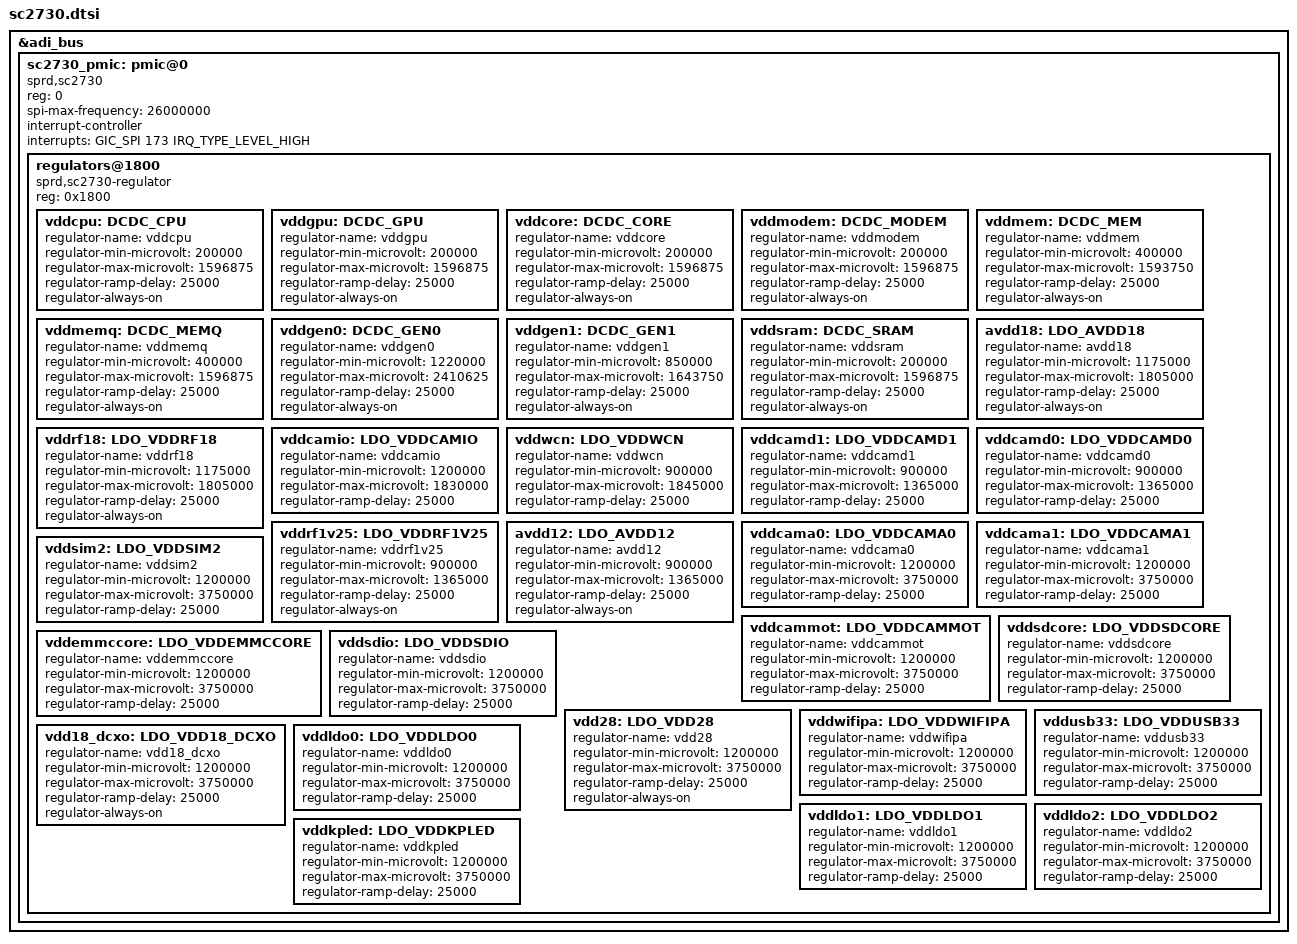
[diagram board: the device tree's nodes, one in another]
// SPDX-License-Identifier: (GPL-2.0 OR MIT)
/*
 * Unisoc SC2730 PMIC dts file
 *
 * Copyright (C) 2021, Unisoc Inc.
 */

&adi_bus {
	sc2730_pmic: pmic@0 {
		compatible = "sprd,sc2730";
		reg = <0>;
		spi-max-frequency = <26000000>;
		interrupt-controller;
		#interrupt-cells = <1>;
		interrupts = <GIC_SPI 173 IRQ_TYPE_LEVEL_HIGH>;
		#address-cells = <1>;
		#size-cells = <0>;

		regulators@1800 {
			compatible = "sprd,sc2730-regulator";
			reg = <0x1800>;

			vddcpu: DCDC_CPU {
				regulator-name = "vddcpu";
				regulator-min-microvolt = <200000>;
				regulator-max-microvolt = <1596875>;
				regulator-ramp-delay = <25000>;
				regulator-always-on;
			};

			vddgpu: DCDC_GPU {
				regulator-name = "vddgpu";
				regulator-min-microvolt = <200000>;
				regulator-max-microvolt = <1596875>;
				regulator-ramp-delay = <25000>;
				regulator-always-on;
			};

			vddcore: DCDC_CORE {
				regulator-name = "vddcore";
				regulator-min-microvolt = <200000>;
				regulator-max-microvolt = <1596875>;
				regulator-ramp-delay = <25000>;
				regulator-always-on;
			};

			vddmodem: DCDC_MODEM {
				regulator-name = "vddmodem";
				regulator-min-microvolt = <200000>;
				regulator-max-microvolt = <1596875>;
				regulator-ramp-delay = <25000>;
				regulator-always-on;
			};

			vddmem: DCDC_MEM {
				regulator-name = "vddmem";
				regulator-min-microvolt = <400000>;
				regulator-max-microvolt = <1593750>;
				regulator-ramp-delay = <25000>;
				regulator-always-on;
			};

			vddmemq: DCDC_MEMQ {
				regulator-name = "vddmemq";
				regulator-min-microvolt = <400000>;
				regulator-max-microvolt = <1596875>;
				regulator-ramp-delay = <25000>;
				regulator-always-on;
			};

			vddgen0: DCDC_GEN0 {
				regulator-name = "vddgen0";
				regulator-min-microvolt = <1220000>;
				regulator-max-microvolt = <2410625>;
				regulator-ramp-delay = <25000>;
				regulator-always-on;
			};

			vddgen1: DCDC_GEN1 {
				regulator-name = "vddgen1";
				regulator-min-microvolt = <850000>;
				regulator-max-microvolt = <1643750>;
				regulator-ramp-delay = <25000>;
				regulator-always-on;
			};

			vddsram: DCDC_SRAM {
				regulator-name = "vddsram";
				regulator-min-microvolt = <200000>;
				regulator-max-microvolt = <1596875>;
				regulator-ramp-delay = <25000>;
				regulator-always-on;
			};

			avdd18: LDO_AVDD18 {
				regulator-name = "avdd18";
				regulator-min-microvolt = <1175000>;
				regulator-max-microvolt = <1805000>;
				regulator-ramp-delay = <25000>;
				regulator-always-on;
			};

			vddrf18: LDO_VDDRF18 {
				regulator-name = "vddrf18";
				regulator-min-microvolt = <1175000>;
				regulator-max-microvolt = <1805000>;
				regulator-ramp-delay = <25000>;
				regulator-always-on;
			};

			vddcamio: LDO_VDDCAMIO {
				regulator-name = "vddcamio";
				regulator-min-microvolt = <1200000>;
				regulator-max-microvolt = <1830000>;
				regulator-ramp-delay = <25000>;
			};

			vddwcn: LDO_VDDWCN {
				regulator-name = "vddwcn";
				regulator-min-microvolt = <900000>;
				regulator-max-microvolt = <1845000>;
				regulator-ramp-delay = <25000>;
			};

			vddcamd1: LDO_VDDCAMD1 {
				regulator-name = "vddcamd1";
				regulator-min-microvolt = <900000>;
				regulator-max-microvolt = <1365000>;
				regulator-ramp-delay = <25000>;
			};

			vddcamd0: LDO_VDDCAMD0 {
				regulator-name = "vddcamd0";
				regulator-min-microvolt = <900000>;
				regulator-max-microvolt = <1365000>;
				regulator-ramp-delay = <25000>;
			};

			vddrf1v25: LDO_VDDRF1V25 {
				regulator-name = "vddrf1v25";
				regulator-min-microvolt = <900000>;
				regulator-max-microvolt = <1365000>;
				regulator-ramp-delay = <25000>;
				regulator-always-on;
			};

			avdd12: LDO_AVDD12 {
				regulator-name = "avdd12";
				regulator-min-microvolt = <900000>;
				regulator-max-microvolt = <1365000>;
				regulator-ramp-delay = <25000>;
				regulator-always-on;
			};

			vddcama0: LDO_VDDCAMA0 {
				regulator-name = "vddcama0";
				regulator-min-microvolt = <1200000>;
				regulator-max-microvolt = <3750000>;
				regulator-ramp-delay = <25000>;
			};

			vddcama1: LDO_VDDCAMA1 {
				regulator-name = "vddcama1";
				regulator-min-microvolt = <1200000>;
				regulator-max-microvolt = <3750000>;
				regulator-ramp-delay = <25000>;
			};

			vddcammot: LDO_VDDCAMMOT {
				regulator-name = "vddcammot";
				regulator-min-microvolt = <1200000>;
				regulator-max-microvolt = <3750000>;
				regulator-ramp-delay = <25000>;
			};

			vddsim2: LDO_VDDSIM2 {
				regulator-name = "vddsim2";
				regulator-min-microvolt = <1200000>;
				regulator-max-microvolt = <3750000>;
				regulator-ramp-delay = <25000>;
			};

			vddemmccore: LDO_VDDEMMCCORE {
				regulator-name = "vddemmccore";
				regulator-min-microvolt = <1200000>;
				regulator-max-microvolt = <3750000>;
				regulator-ramp-delay = <25000>;
			};

			vddsdcore: LDO_VDDSDCORE {
				regulator-name = "vddsdcore";
				regulator-min-microvolt = <1200000>;
				regulator-max-microvolt = <3750000>;
				regulator-ramp-delay = <25000>;
			};

			vddsdio: LDO_VDDSDIO {
				regulator-name = "vddsdio";
				regulator-min-microvolt = <1200000>;
				regulator-max-microvolt = <3750000>;
				regulator-ramp-delay = <25000>;
			};

			vdd28: LDO_VDD28 {
				regulator-name = "vdd28";
				regulator-min-microvolt = <1200000>;
				regulator-max-microvolt = <3750000>;
				regulator-ramp-delay = <25000>;
				regulator-always-on;
			};

			vddwifipa: LDO_VDDWIFIPA {
				regulator-name = "vddwifipa";
				regulator-min-microvolt = <1200000>;
				regulator-max-microvolt = <3750000>;
				regulator-ramp-delay = <25000>;
			};

			vdd18_dcxo: LDO_VDD18_DCXO {
				regulator-name = "vdd18_dcxo";
				regulator-min-microvolt = <1200000>;
				regulator-max-microvolt = <3750000>;
				regulator-ramp-delay = <25000>;
				regulator-always-on;
			};

			vddusb33: LDO_VDDUSB33 {
				regulator-name = "vddusb33";
				regulator-min-microvolt = <1200000>;
				regulator-max-microvolt = <3750000>;
				regulator-ramp-delay = <25000>;
			};

			vddldo0: LDO_VDDLDO0 {
				regulator-name = "vddldo0";
				regulator-min-microvolt = <1200000>;
				regulator-max-microvolt = <3750000>;
				regulator-ramp-delay = <25000>;
			};

			vddldo1: LDO_VDDLDO1 {
				regulator-name = "vddldo1";
				regulator-min-microvolt = <1200000>;
				regulator-max-microvolt = <3750000>;
				regulator-ramp-delay = <25000>;
			};

			vddldo2: LDO_VDDLDO2 {
				regulator-name = "vddldo2";
				regulator-min-microvolt = <1200000>;
				regulator-max-microvolt = <3750000>;
				regulator-ramp-delay = <25000>;
			};

			vddkpled: LDO_VDDKPLED {
				regulator-name = "vddkpled";
				regulator-min-microvolt = <1200000>;
				regulator-max-microvolt = <3750000>;
				regulator-ramp-delay = <25000>;
			};
		};
	};
};
